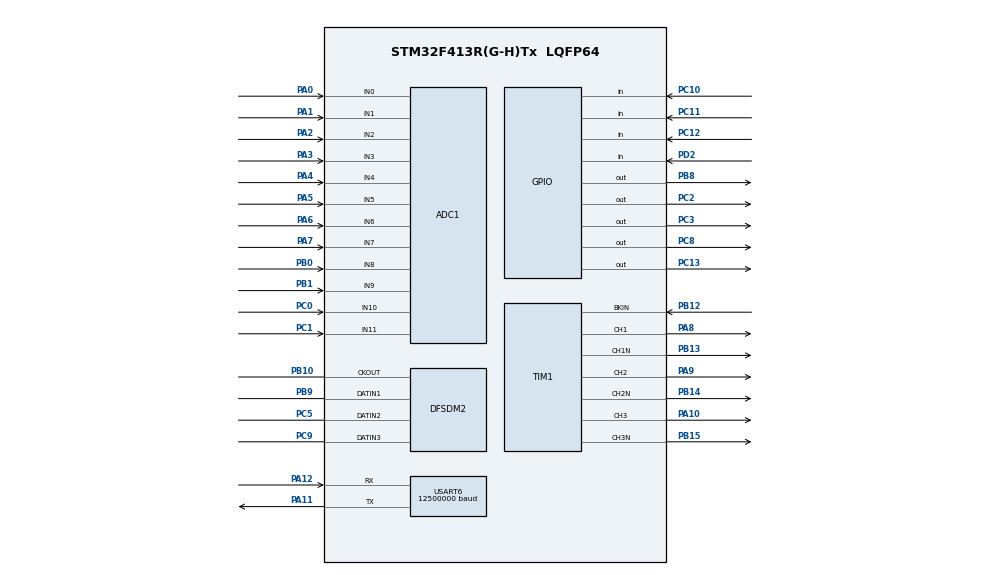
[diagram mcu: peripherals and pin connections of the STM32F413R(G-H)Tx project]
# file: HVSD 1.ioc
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ADC1.Channel-0\#ChannelRegularConversion=ADC_CHANNEL_0
ADC1.NbrOfConversionFlag=1
ADC1.Rank-0\#ChannelRegularConversion=1
ADC1.SamplingTime-0\#ChannelRegularConversion=ADC_SAMPLETIME_3CYCLES
ADC1.master=1
DFSDM2.Divider=11
DFSDM2.FilterOrder_CH0=DFSDM_CHANNEL_FASTSINC_ORDER
DFSDM2.Filter_regChannel_FIL0=DFSDM_CHANNEL_0
DFSDM2.Filter_regChannel_FIL1=DFSDM_CHANNEL_1
DFSDM2.Filter_regChannel_FIL2=DFSDM_CHANNEL_2
DFSDM2.Fosr_FIL0=256
DFSDM2.Fosr_FIL1=256
DFSDM2.Fosr_FIL2=256
DFSDM2.SincOrder_FIL0=DFSDM_FILTER_SINC3_ORDER
DFSDM2.SincOrder_FIL1=DFSDM_FILTER_SINC3_ORDER
DFSDM2.SincOrder_FIL2=DFSDM_FILTER_SINC3_ORDER
Dma.Request0=TIM1_CH1/CH2/CH3
Dma.TIM1_CH1/CH2/CH3.0.Direction=DMA_MEMORY_TO_PERIPH
Dma.TIM1_CH1/CH2/CH3.0.FIFOMode=DMA_FIFOMODE_DISABLE
Dma.TIM1_CH1/CH2/CH3.0.Instance=DMA2_Stream6
Dma.TIM1_CH1/CH2/CH3.0.MemDataAlignment=DMA_MDATAALIGN_HALFWORD
Dma.TIM1_CH1/CH2/CH3.0.MemInc=DMA_MINC_ENABLE
Dma.TIM1_CH1/CH2/CH3.0.Mode=DMA_NORMAL
Dma.TIM1_CH1/CH2/CH3.0.PeriphDataAlignment=DMA_PDATAALIGN_HALFWORD
Dma.TIM1_CH1/CH2/CH3.0.PeriphInc=DMA_PINC_DISABLE
Dma.TIM1_CH1/CH2/CH3.0.Priority=DMA_PRIORITY_HIGH
Mcu.Family=STM32F4
Mcu.Name=STM32F413R(G-H)Tx
Mcu.Package=LQFP64
NVIC.DMA2_Stream6_IRQn=true\:0\:0\:false\:false\:true\:false\:true\:true
NVIC.PriorityGroup=NVIC_PRIORITYGROUP_4
PA0.Signal=ADCx_IN0
PA1.Signal=ADCx_IN1
PA10.Signal=S_TIM1_CH3
PA11.Mode=Asynchronous
PA11.Signal=USART6_TX
PA12.Mode=Asynchronous
PA12.Signal=USART6_RX
PA13.Signal=SYS_JTMS-SWDIO
PA14.Signal=SYS_JTCK-SWCLK
PA2.Signal=ADCx_IN2
PA3.Signal=ADCx_IN3
PA4.Signal=ADCx_IN4
PA5.Signal=ADCx_IN5
PA6.Signal=ADCx_IN6
PA7.Signal=ADCx_IN7
PA8.Signal=S_TIM1_CH1
PA9.Signal=S_TIM1_CH2
PB0.Signal=ADCx_IN8
PB1.Signal=ADCx_IN9
PB10.Signal=S_CKOUTDFSDM2
PB12.Mode=Activate-Break-Input
PB12.Signal=TIM1_BKIN
PB13.Mode=PWM Generation1 CH1 CH1N
PB13.Signal=TIM1_CH1N
PB14.Mode=PWM Generation2 CH2 CH2N
PB14.Signal=TIM1_CH2N
PB15.Mode=PWM Generation3 CH3 CH3N
PB15.Signal=TIM1_CH3N
PB3.Signal=SYS_JTDO-SWO
PB6.Signal=S_TIM4_CH1
PB8.Signal=GPIO_Output
PB9.Signal=S_DATAIN1DFSDM2
PC0.Signal=ADCx_IN10
PC1.Signal=ADCx_IN11
PC10.Signal=GPIO_Input
PC11.Signal=GPIO_Input
PC12.Signal=GPIO_Input
PC13.Signal=GPIO_Output
PC2.Signal=GPIO_Output
PC3.Signal=GPIO_Output
PC5.Signal=S_DATAIN2DFSDM2
PC6.Signal=S_TIM3_CH1
PC7.Signal=S_TIM3_CH2
PC8.Signal=GPIO_Output
PC9.Signal=S_DATAIN3DFSDM2
PD2.Signal=GPIO_Input
ProjectManager.HeapSize=0x200
ProjectManager.StackSize=0x400
ProjectManager.TargetToolchain=STM32CubeIDE
RCC.AHBFreq_Value=100000000
RCC.APB1CLKDivider=RCC_HCLK_DIV2
RCC.APB1Freq_Value=50000000
RCC.APB1TimFreq_Value=100000000
RCC.APB2Freq_Value=100000000
RCC.APB2TimFreq_Value=100000000
RCC.CortexFreq_Value=100000000
RCC.DFSDMSelection=RCC_DFSDM1CLKSOURCE_SYSCLK
RCC.HCLKFreq_Value=100000000
RCC.PLLI2SN=200
RCC.PLLN=200
RCC.SYSCLKFreq_VALUE=100000000
RCC.SYSCLKSource=RCC_SYSCLKSOURCE_PLLCLK
RCC.USBFreq_Value=100000000
RCC.VCOOutputFreq_Value=200000000
SH.ADCx_IN0.0=ADC1_IN0,IN0
SH.ADCx_IN1.0=ADC1_IN1,IN1
SH.ADCx_IN10.0=ADC1_IN10,IN10
SH.ADCx_IN11.0=ADC1_IN11,IN11
SH.ADCx_IN2.0=ADC1_IN2,IN2
SH.ADCx_IN3.0=ADC1_IN3,IN3
SH.ADCx_IN4.0=ADC1_IN4,IN4
SH.ADCx_IN5.0=ADC1_IN5,IN5
SH.ADCx_IN6.0=ADC1_IN6,IN6
SH.ADCx_IN7.0=ADC1_IN7,IN7
SH.ADCx_IN8.0=ADC1_IN8,IN8
SH.ADCx_IN9.0=ADC1_IN9,IN9
SH.S_CKOUTDFSDM2.0=DFSDM2_CKOUT,PDM_SPI_Input_from_ch12_and_Internal_Clock
SH.S_CKOUTDFSDM2.1=DFSDM2_CKOUT,PDM_SPI_Input_from_ch01_and_Internal_Clock
SH.S_CKOUTDFSDM2.2=DFSDM2_CKOUT,PDM_SPI_Input_from_ch23_and_Internal_Clock
SH.S_CKOUTDFSDM2.3=DFSDM2_CKOUT,CKOUT
SH.S_DATAIN1DFSDM2.0=DFSDM2_DATIN1,PDM_SPI_Input_from_ch01_and_Internal_Clock
SH.S_DATAIN2DFSDM2.0=DFSDM2_DATIN2,PDM_SPI_Input_from_ch12_and_Internal_Clock
SH.S_DATAIN3DFSDM2.0=DFSDM2_DATIN3,PDM_SPI_Input_from_ch23_and_Internal_Clock
SH.S_TIM1_CH1.0=TIM1_CH1,PWM Generation1 CH1 CH1N
SH.S_TIM1_CH2.0=TIM1_CH2,PWM Generation2 CH2 CH2N
SH.S_TIM1_CH3.0=TIM1_CH3,PWM Generation3 CH3 CH3N
SH.S_TIM3_CH1.0=TIM3_CH1
SH.S_TIM3_CH2.0=TIM3_CH2
SH.S_TIM4_CH1.0=TIM4_CH1
TIM1.AutoReloadPreload=TIM_AUTORELOAD_PRELOAD_ENABLE
TIM1.Channel-PWM\ Generation1\ CH1\ CH1N=TIM_CHANNEL_1
TIM1.Channel-PWM\ Generation2\ CH2\ CH2N=TIM_CHANNEL_2
TIM1.Channel-PWM\ Generation3\ CH3\ CH3N=TIM_CHANNEL_3
TIM1.Channel-PWM\ Generation4\ No\ Output=TIM_CHANNEL_4
TIM1.CounterMode=TIM_COUNTERMODE_CENTERALIGNED1
TIM1.OCMode_PWM-PWM\ Generation1\ CH1\ CH1N=TIM_OCMODE_PWM1
USART6.BaudRate=12500000
USART6.OverSampling=UART_OVERSAMPLING_8
USART6.VirtualMode=VM_ASYNC
VP_CRC_VS_CRC.Mode=CRC_Activate
VP_TIM1_VS_ClockSourceITR.Mode=TriggerSource_ITR1
VP_TIM1_VS_ControllerModeTrigger.Mode=Trigger Mode
VP_TIM1_VS_no_output4.Mode=PWM Generation4 No Output
board=custom

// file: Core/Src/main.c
/* USER CODE BEGIN Header */
/**
  ******************************************************************************
  * @file           : main.c
  * @brief          : Main program body
  ******************************************************************************
  * @attention
  *
  * <h2><center>&copy; Copyright (c) 2023 STMicroelectronics.
  * All rights reserved.</center></h2>
  *
  * This software component is licensed by ST under BSD 3-Clause license,
  * the "License"; You may not use this file except in compliance with the
  * License. You may obtain a copy of the License at:
  *                        opensource.org/licenses/BSD-3-Clause
  *
  ******************************************************************************
  */
/* USER CODE END Header */
#include "main.h"

/* USER CODE BEGIN Includes */
#include "stdio.h"
/* USER CODE END Includes */

DFSDM_Filter_HandleTypeDef hdfsdm2_filter0;
DFSDM_Filter_HandleTypeDef hdfsdm2_filter1;
DFSDM_Filter_HandleTypeDef hdfsdm2_filter2;
DFSDM_Channel_HandleTypeDef hdfsdm2_channel0;
DFSDM_Channel_HandleTypeDef hdfsdm2_channel1;
DFSDM_Channel_HandleTypeDef hdfsdm2_channel2;

void SystemClock_Config(void);
static void MX_GPIO_Init(void);
static void MX_DMA_Init(void);
static void MX_ADC1_Init(void);
static void MX_TIM1_Init(void);
static void MX_DFSDM2_Init(void);
static void MX_USART6_UART_Init(void);
static void MX_CRC_Init(void);

int main(void)
{

  /* MCU Configuration--------------------------------------------------------*/

  /* Reset of all peripherals, Initializes the Flash interface and the Systick. */
  HAL_Init();

  /* Configure the system clock */
  SystemClock_Config();

  /* Initialize all configured peripherals */
  MX_GPIO_Init();
  MX_DMA_Init();
  MX_ADC1_Init();
  MX_TIM1_Init();
  MX_DFSDM2_Init();
  MX_USART6_UART_Init();
  MX_CRC_Init();
  /* USER CODE BEGIN 2 */
  MX_MotorControl_Init();
  /* USER CODE END 2 */

  /* Infinite loop */
  while (1)
  {
    /* USER CODE BEGIN 3 */
	  printf("hello");
	  HAL_GPIO_TogglePin(GPIOB, GPIO_PIN_8);
	  //HAL_GPIO_TogglePin(GPIOC, GPIO_PIN_13);
	  //HAL_GPIO_TogglePin(GPIOC, GPIO_PIN_2);
	  HAL_GPIO_TogglePin(GPIOC, GPIO_PIN_3);
	  HAL_Delay(1);
  }
  /* USER CODE END 3 */
}

void SystemClock_Config(void)
{
  LL_FLASH_SetLatency(LL_FLASH_LATENCY_3);
  while(LL_FLASH_GetLatency()!= LL_FLASH_LATENCY_3)
  {
  }
  LL_PWR_SetRegulVoltageScaling(LL_PWR_REGU_VOLTAGE_SCALE1);
  LL_RCC_HSI_SetCalibTrimming(16);
  LL_RCC_HSI_Enable();

   /* Wait till HSI is ready */
  while(LL_RCC_HSI_IsReady() != 1)
  {

  }
  LL_RCC_PLL_ConfigDomain_SYS(LL_RCC_PLLSOURCE_HSI, LL_RCC_PLLM_DIV_16, 200, LL_RCC_PLLP_DIV_2);
  LL_RCC_PLL_Enable();

   /* Wait till PLL is ready */
  while(LL_RCC_PLL_IsReady() != 1)
  {

  }
  while (LL_PWR_IsActiveFlag_VOS() == 0)
  {
  }
  LL_RCC_SetAHBPrescaler(LL_RCC_SYSCLK_DIV_1);
  LL_RCC_SetAPB1Prescaler(LL_RCC_APB1_DIV_2);
  LL_RCC_SetAPB2Prescaler(LL_RCC_APB2_DIV_1);
  LL_RCC_SetSysClkSource(LL_RCC_SYS_CLKSOURCE_PLL);

   /* Wait till System clock is ready */
  while(LL_RCC_GetSysClkSource() != LL_RCC_SYS_CLKSOURCE_STATUS_PLL)
  {

  }
  LL_SetSystemCoreClock(100000000);

   /* Update the time base */
  if (HAL_InitTick (TICK_INT_PRIORITY) != HAL_OK)
  {
    Error_Handler();
  }
  LL_RCC_SetTIMPrescaler(LL_RCC_TIM_PRESCALER_TWICE);
}

static void MX_ADC1_Init(void)
{

  LL_ADC_InitTypeDef ADC_InitStruct = {0};
  LL_ADC_REG_InitTypeDef ADC_REG_InitStruct = {0};
  LL_ADC_CommonInitTypeDef ADC_CommonInitStruct = {0};

  LL_GPIO_InitTypeDef GPIO_InitStruct = {0};

  /* Peripheral clock enable */
  LL_APB2_GRP1_EnableClock(LL_APB2_GRP1_PERIPH_ADC1);

  LL_AHB1_GRP1_EnableClock(LL_AHB1_GRP1_PERIPH_GPIOC);
  LL_AHB1_GRP1_EnableClock(LL_AHB1_GRP1_PERIPH_GPIOA);
  LL_AHB1_GRP1_EnableClock(LL_AHB1_GRP1_PERIPH_GPIOB);
  /**ADC1 GPIO Configuration
  PC0   ------> ADC1_IN10
  PC1   ------> ADC1_IN11
  PA0   ------> ADC1_IN0
  PA1   ------> ADC1_IN1
  PA2   ------> ADC1_IN2
  PA3   ------> ADC1_IN3
  PA4   ------> ADC1_IN4
  PA5   ------> ADC1_IN5
  PA6   ------> ADC1_IN6
  PA7   ------> ADC1_IN7
  PB0   ------> ADC1_IN8
  PB1   ------> ADC1_IN9
  */
  GPIO_InitStruct.Pin = LL_GPIO_PIN_0|LL_GPIO_PIN_1;
  GPIO_InitStruct.Mode = LL_GPIO_MODE_ANALOG;
  GPIO_InitStruct.Pull = LL_GPIO_PULL_NO;
  LL_GPIO_Init(GPIOC, &GPIO_InitStruct);

  GPIO_InitStruct.Pin = LL_GPIO_PIN_0|LL_GPIO_PIN_1|LL_GPIO_PIN_2|LL_GPIO_PIN_3
                          |LL_GPIO_PIN_4|LL_GPIO_PIN_5|LL_GPIO_PIN_6|LL_GPIO_PIN_7;
  GPIO_InitStruct.Mode = LL_GPIO_MODE_ANALOG;
  GPIO_InitStruct.Pull = LL_GPIO_PULL_NO;
  LL_GPIO_Init(GPIOA, &GPIO_InitStruct);

  GPIO_InitStruct.Pin = LL_GPIO_PIN_0|LL_GPIO_PIN_1;
  GPIO_InitStruct.Mode = LL_GPIO_MODE_ANALOG;
  GPIO_InitStruct.Pull = LL_GPIO_PULL_NO;
  LL_GPIO_Init(GPIOB, &GPIO_InitStruct);

  /** Common config
  */
  ADC_InitStruct.Resolution = LL_ADC_RESOLUTION_12B;
  ADC_InitStruct.DataAlignment = LL_ADC_DATA_ALIGN_RIGHT;
  ADC_InitStruct.SequencersScanMode = LL_ADC_SEQ_SCAN_DISABLE;
  LL_ADC_Init(ADC1, &ADC_InitStruct);
  ADC_REG_InitStruct.TriggerSource = LL_ADC_REG_TRIG_SOFTWARE;
  ADC_REG_InitStruct.SequencerLength = LL_ADC_REG_SEQ_SCAN_DISABLE;
  ADC_REG_InitStruct.SequencerDiscont = LL_ADC_REG_SEQ_DISCONT_DISABLE;
  ADC_REG_InitStruct.ContinuousMode = LL_ADC_REG_CONV_SINGLE;
  ADC_REG_InitStruct.DMATransfer = LL_ADC_REG_DMA_TRANSFER_NONE;
  LL_ADC_REG_Init(ADC1, &ADC_REG_InitStruct);
  LL_ADC_REG_SetFlagEndOfConversion(ADC1, LL_ADC_REG_FLAG_EOC_UNITARY_CONV);
  ADC_CommonInitStruct.CommonClock = LL_ADC_CLOCK_SYNC_PCLK_DIV4;
  LL_ADC_CommonInit(__LL_ADC_COMMON_INSTANCE(ADC1), &ADC_CommonInitStruct);

  /** Configure Regular Channel
  */
  LL_ADC_REG_SetSequencerRanks(ADC1, LL_ADC_REG_RANK_1, LL_ADC_CHANNEL_0);
  LL_ADC_SetChannelSamplingTime(ADC1, LL_ADC_CHANNEL_0, LL_ADC_SAMPLINGTIME_3CYCLES);

}

static void MX_CRC_Init(void)
{

  /* Peripheral clock enable */
  LL_AHB1_GRP1_EnableClock(LL_AHB1_GRP1_PERIPH_CRC);

}

static void MX_DFSDM2_Init(void)
{

  hdfsdm2_filter0.Instance = DFSDM2_Filter0;
  hdfsdm2_filter0.Init.RegularParam.Trigger = DFSDM_FILTER_SW_TRIGGER;
  hdfsdm2_filter0.Init.RegularParam.FastMode = DISABLE;
  hdfsdm2_filter0.Init.RegularParam.DmaMode = DISABLE;
  hdfsdm2_filter0.Init.FilterParam.SincOrder = DFSDM_FILTER_SINC3_ORDER;
  hdfsdm2_filter0.Init.FilterParam.Oversampling = 256;
  hdfsdm2_filter0.Init.FilterParam.IntOversampling = 1;
  if (HAL_DFSDM_FilterInit(&hdfsdm2_filter0) != HAL_OK)
  {
    Error_Handler();
  }
  hdfsdm2_filter1.Instance = DFSDM2_Filter1;
  hdfsdm2_filter1.Init.RegularParam.Trigger = DFSDM_FILTER_SW_TRIGGER;
  hdfsdm2_filter1.Init.RegularParam.FastMode = DISABLE;
  hdfsdm2_filter1.Init.RegularParam.DmaMode = DISABLE;
  hdfsdm2_filter1.Init.FilterParam.SincOrder = DFSDM_FILTER_SINC3_ORDER;
  hdfsdm2_filter1.Init.FilterParam.Oversampling = 256;
  hdfsdm2_filter1.Init.FilterParam.IntOversampling = 1;
  if (HAL_DFSDM_FilterInit(&hdfsdm2_filter1) != HAL_OK)
  {
    Error_Handler();
  }
  hdfsdm2_filter2.Instance = DFSDM2_Filter2;
  hdfsdm2_filter2.Init.RegularParam.Trigger = DFSDM_FILTER_SW_TRIGGER;
  hdfsdm2_filter2.Init.RegularParam.FastMode = DISABLE;
  hdfsdm2_filter2.Init.RegularParam.DmaMode = DISABLE;
  hdfsdm2_filter2.Init.FilterParam.SincOrder = DFSDM_FILTER_SINC3_ORDER;
  hdfsdm2_filter2.Init.FilterParam.Oversampling = 256;
  hdfsdm2_filter2.Init.FilterParam.IntOversampling = 1;
  if (HAL_DFSDM_FilterInit(&hdfsdm2_filter2) != HAL_OK)
  {
    Error_Handler();
  }
  hdfsdm2_channel0.Instance = DFSDM2_Channel0;
  hdfsdm2_channel0.Init.OutputClock.Activation = ENABLE;
  hdfsdm2_channel0.Init.OutputClock.Selection = DFSDM_CHANNEL_OUTPUT_CLOCK_SYSTEM;
  hdfsdm2_channel0.Init.OutputClock.Divider = 11;
  hdfsdm2_channel0.Init.Input.Multiplexer = DFSDM_CHANNEL_EXTERNAL_INPUTS;
  hdfsdm2_channel0.Init.Input.DataPacking = DFSDM_CHANNEL_STANDARD_MODE;
  hdfsdm2_channel0.Init.Input.Pins = DFSDM_CHANNEL_FOLLOWING_CHANNEL_PINS;
  hdfsdm2_channel0.Init.SerialInterface.Type = DFSDM_CHANNEL_SPI_RISING;
  hdfsdm2_channel0.Init.SerialInterface.SpiClock = DFSDM_CHANNEL_SPI_CLOCK_INTERNAL;
  hdfsdm2_channel0.Init.Awd.FilterOrder = DFSDM_CHANNEL_FASTSINC_ORDER;
  hdfsdm2_channel0.Init.Awd.Oversampling = 1;
  hdfsdm2_channel0.Init.Offset = 0;
  hdfsdm2_channel0.Init.RightBitShift = 0x00;
  if (HAL_DFSDM_ChannelInit(&hdfsdm2_channel0) != HAL_OK)
  {
    Error_Handler();
  }
  hdfsdm2_channel1.Instance = DFSDM2_Channel1;
  hdfsdm2_channel1.Init.OutputClock.Activation = ENABLE;
  hdfsdm2_channel1.Init.OutputClock.Selection = DFSDM_CHANNEL_OUTPUT_CLOCK_SYSTEM;
  hdfsdm2_channel1.Init.OutputClock.Divider = 11;
  hdfsdm2_channel1.Init.Input.Multiplexer = DFSDM_CHANNEL_EXTERNAL_INPUTS;
  hdfsdm2_channel1.Init.Input.DataPacking = DFSDM_CHANNEL_STANDARD_MODE;
  hdfsdm2_channel1.Init.Input.Pins = DFSDM_CHANNEL_FOLLOWING_CHANNEL_PINS;
  hdfsdm2_channel1.Init.SerialInterface.Type = DFSDM_CHANNEL_SPI_RISING;
  hdfsdm2_channel1.Init.SerialInterface.SpiClock = DFSDM_CHANNEL_SPI_CLOCK_INTERNAL;
  hdfsdm2_channel1.Init.Awd.FilterOrder = DFSDM_CHANNEL_FASTSINC_ORDER;
  hdfsdm2_channel1.Init.Awd.Oversampling = 1;
  hdfsdm2_channel1.Init.Offset = 0;
  hdfsdm2_channel1.Init.RightBitShift = 0x00;
  if (HAL_DFSDM_ChannelInit(&hdfsdm2_channel1) != HAL_OK)
  {
    Error_Handler();
  }
  hdfsdm2_channel2.Instance = DFSDM2_Channel2;
  hdfsdm2_channel2.Init.OutputClock.Activation = ENABLE;
  hdfsdm2_channel2.Init.OutputClock.Selection = DFSDM_CHANNEL_OUTPUT_CLOCK_SYSTEM;
  hdfsdm2_channel2.Init.OutputClock.Divider = 11;
  hdfsdm2_channel2.Init.Input.Multiplexer = DFSDM_CHANNEL_EXTERNAL_INPUTS;
  hdfsdm2_channel2.Init.Input.DataPacking = DFSDM_CHANNEL_STANDARD_MODE;
  hdfsdm2_channel2.Init.Input.Pins = DFSDM_CHANNEL_FOLLOWING_CHANNEL_PINS;
  hdfsdm2_channel2.Init.SerialInterface.Type = DFSDM_CHANNEL_SPI_RISING;
  hdfsdm2_channel2.Init.SerialInterface.SpiClock = DFSDM_CHANNEL_SPI_CLOCK_INTERNAL;
  hdfsdm2_channel2.Init.Awd.FilterOrder = DFSDM_CHANNEL_FASTSINC_ORDER;
  hdfsdm2_channel2.Init.Awd.Oversampling = 1;
  hdfsdm2_channel2.Init.Offset = 0;
  hdfsdm2_channel2.Init.RightBitShift = 0x00;
  if (HAL_DFSDM_ChannelInit(&hdfsdm2_channel2) != HAL_OK)
  {
    Error_Handler();
  }
  if (HAL_DFSDM_FilterConfigRegChannel(&hdfsdm2_filter0, DFSDM_CHANNEL_0, DFSDM_CONTINUOUS_CONV_ON) != HAL_OK)
  {
    Error_Handler();
  }
  if (HAL_DFSDM_FilterConfigRegChannel(&hdfsdm2_filter1, DFSDM_CHANNEL_1, DFSDM_CONTINUOUS_CONV_ON) != HAL_OK)
  {
    Error_Handler();
  }
  if (HAL_DFSDM_FilterConfigRegChannel(&hdfsdm2_filter2, DFSDM_CHANNEL_2, DFSDM_CONTINUOUS_CONV_ON) != HAL_OK)
  {
    Error_Handler();
  }

}

static void MX_TIM1_Init(void)
{

  LL_TIM_InitTypeDef TIM_InitStruct = {0};
  LL_TIM_OC_InitTypeDef TIM_OC_InitStruct = {0};
  LL_TIM_BDTR_InitTypeDef TIM_BDTRInitStruct = {0};

  LL_GPIO_InitTypeDef GPIO_InitStruct = {0};

  /* Peripheral clock enable */
  LL_APB2_GRP1_EnableClock(LL_APB2_GRP1_PERIPH_TIM1);

  LL_AHB1_GRP1_EnableClock(LL_AHB1_GRP1_PERIPH_GPIOB);
  /**TIM1 GPIO Configuration
  PB12   ------> TIM1_BKIN
  */
  GPIO_InitStruct.Pin = LL_GPIO_PIN_12;
  GPIO_InitStruct.Mode = LL_GPIO_MODE_ALTERNATE;
  GPIO_InitStruct.Speed = LL_GPIO_SPEED_FREQ_LOW;
  GPIO_InitStruct.OutputType = LL_GPIO_OUTPUT_PUSHPULL;
  GPIO_InitStruct.Pull = LL_GPIO_PULL_NO;
  GPIO_InitStruct.Alternate = LL_GPIO_AF_1;
  LL_GPIO_Init(GPIOB, &GPIO_InitStruct);

  /* TIM1 DMA Init */

  /* TIM1_CH1_CH2_CH3 Init */
  LL_DMA_SetChannelSelection(DMA2, LL_DMA_STREAM_6, LL_DMA_CHANNEL_0);

  LL_DMA_SetDataTransferDirection(DMA2, LL_DMA_STREAM_6, LL_DMA_DIRECTION_MEMORY_TO_PERIPH);

  LL_DMA_SetStreamPriorityLevel(DMA2, LL_DMA_STREAM_6, LL_DMA_PRIORITY_HIGH);

  LL_DMA_SetMode(DMA2, LL_DMA_STREAM_6, LL_DMA_MODE_NORMAL);

  LL_DMA_SetPeriphIncMode(DMA2, LL_DMA_STREAM_6, LL_DMA_PERIPH_NOINCREMENT);

  LL_DMA_SetMemoryIncMode(DMA2, LL_DMA_STREAM_6, LL_DMA_MEMORY_INCREMENT);

  LL_DMA_SetPeriphSize(DMA2, LL_DMA_STREAM_6, LL_DMA_PDATAALIGN_HALFWORD);

  LL_DMA_SetMemorySize(DMA2, LL_DMA_STREAM_6, LL_DMA_MDATAALIGN_HALFWORD);

  LL_DMA_DisableFifoMode(DMA2, LL_DMA_STREAM_6);

  TIM_InitStruct.Prescaler = 0;
  TIM_InitStruct.CounterMode = LL_TIM_COUNTERMODE_CENTER_DOWN;
  TIM_InitStruct.Autoreload = 65535;
  TIM_InitStruct.ClockDivision = LL_TIM_CLOCKDIVISION_DIV1;
  TIM_InitStruct.RepetitionCounter = 0;
  LL_TIM_Init(TIM1, &TIM_InitStruct);
  LL_TIM_EnableARRPreload(TIM1);
  LL_TIM_OC_EnablePreload(TIM1, LL_TIM_CHANNEL_CH1);
  TIM_OC_InitStruct.OCMode = LL_TIM_OCMODE_PWM1;
  TIM_OC_InitStruct.OCState = LL_TIM_OCSTATE_DISABLE;
  TIM_OC_InitStruct.OCNState = LL_TIM_OCSTATE_DISABLE;
  TIM_OC_InitStruct.CompareValue = 0;
  TIM_OC_InitStruct.OCPolarity = LL_TIM_OCPOLARITY_HIGH;
  TIM_OC_InitStruct.OCNPolarity = LL_TIM_OCPOLARITY_HIGH;
  TIM_OC_InitStruct.OCIdleState = LL_TIM_OCIDLESTATE_LOW;
  TIM_OC_InitStruct.OCNIdleState = LL_TIM_OCIDLESTATE_LOW;
  LL_TIM_OC_Init(TIM1, LL_TIM_CHANNEL_CH1, &TIM_OC_InitStruct);
  LL_TIM_OC_DisableFast(TIM1, LL_TIM_CHANNEL_CH1);
  LL_TIM_OC_EnablePreload(TIM1, LL_TIM_CHANNEL_CH2);
  LL_TIM_OC_Init(TIM1, LL_TIM_CHANNEL_CH2, &TIM_OC_InitStruct);
  LL_TIM_OC_DisableFast(TIM1, LL_TIM_CHANNEL_CH2);
  LL_TIM_OC_EnablePreload(TIM1, LL_TIM_CHANNEL_CH3);
  LL_TIM_OC_Init(TIM1, LL_TIM_CHANNEL_CH3, &TIM_OC_InitStruct);
  LL_TIM_OC_DisableFast(TIM1, LL_TIM_CHANNEL_CH3);
  LL_TIM_OC_EnablePreload(TIM1, LL_TIM_CHANNEL_CH4);
  LL_TIM_OC_Init(TIM1, LL_TIM_CHANNEL_CH4, &TIM_OC_InitStruct);
  LL_TIM_OC_DisableFast(TIM1, LL_TIM_CHANNEL_CH4);
  LL_TIM_SetTriggerInput(TIM1, LL_TIM_TS_ITR1);
  LL_TIM_SetSlaveMode(TIM1, LL_TIM_SLAVEMODE_TRIGGER);
  LL_TIM_DisableIT_TRIG(TIM1);
  LL_TIM_DisableDMAReq_TRIG(TIM1);
  LL_TIM_SetTriggerOutput(TIM1, LL_TIM_TRGO_RESET);
  LL_TIM_DisableMasterSlaveMode(TIM1);
  TIM_BDTRInitStruct.OSSRState = LL_TIM_OSSR_DISABLE;
  TIM_BDTRInitStruct.OSSIState = LL_TIM_OSSI_DISABLE;
  TIM_BDTRInitStruct.LockLevel = LL_TIM_LOCKLEVEL_OFF;
  TIM_BDTRInitStruct.DeadTime = 0;
  TIM_BDTRInitStruct.BreakState = LL_TIM_BREAK_ENABLE;
  TIM_BDTRInitStruct.BreakPolarity = LL_TIM_BREAK_POLARITY_HIGH;
  TIM_BDTRInitStruct.AutomaticOutput = LL_TIM_AUTOMATICOUTPUT_DISABLE;
  LL_TIM_BDTR_Init(TIM1, &TIM_BDTRInitStruct);
  LL_AHB1_GRP1_EnableClock(LL_AHB1_GRP1_PERIPH_GPIOB);
  LL_AHB1_GRP1_EnableClock(LL_AHB1_GRP1_PERIPH_GPIOA);
  /**TIM1 GPIO Configuration
  PB13   ------> TIM1_CH1N
  PB14   ------> TIM1_CH2N
  PB15   ------> TIM1_CH3N
  PA8   ------> TIM1_CH1
  PA9   ------> TIM1_CH2
  PA10   ------> TIM1_CH3
  */
  GPIO_InitStruct.Pin = LL_GPIO_PIN_13|LL_GPIO_PIN_14|LL_GPIO_PIN_15;
  GPIO_InitStruct.Mode = LL_GPIO_MODE_ALTERNATE;
  GPIO_InitStruct.Speed = LL_GPIO_SPEED_FREQ_LOW;
  GPIO_InitStruct.OutputType = LL_GPIO_OUTPUT_PUSHPULL;
  GPIO_InitStruct.Pull = LL_GPIO_PULL_NO;
  GPIO_InitStruct.Alternate = LL_GPIO_AF_1;
  LL_GPIO_Init(GPIOB, &GPIO_InitStruct);

  GPIO_InitStruct.Pin = LL_GPIO_PIN_8|LL_GPIO_PIN_9|LL_GPIO_PIN_10;
  GPIO_InitStruct.Mode = LL_GPIO_MODE_ALTERNATE;
  GPIO_InitStruct.Speed = LL_GPIO_SPEED_FREQ_LOW;
  GPIO_InitStruct.OutputType = LL_GPIO_OUTPUT_PUSHPULL;
  GPIO_InitStruct.Pull = LL_GPIO_PULL_NO;
  GPIO_InitStruct.Alternate = LL_GPIO_AF_1;
  LL_GPIO_Init(GPIOA, &GPIO_InitStruct);

}

static void MX_USART6_UART_Init(void)
{

  LL_USART_InitTypeDef USART_InitStruct = {0};

  LL_GPIO_InitTypeDef GPIO_InitStruct = {0};

  /* Peripheral clock enable */
  LL_APB2_GRP1_EnableClock(LL_APB2_GRP1_PERIPH_USART6);

  LL_AHB1_GRP1_EnableClock(LL_AHB1_GRP1_PERIPH_GPIOA);
  /**USART6 GPIO Configuration
  PA11   ------> USART6_TX
  PA12   ------> USART6_RX
  */
  GPIO_InitStruct.Pin = LL_GPIO_PIN_11|LL_GPIO_PIN_12;
  GPIO_InitStruct.Mode = LL_GPIO_MODE_ALTERNATE;
  GPIO_InitStruct.Speed = LL_GPIO_SPEED_FREQ_VERY_HIGH;
  GPIO_InitStruct.OutputType = LL_GPIO_OUTPUT_PUSHPULL;
  GPIO_InitStruct.Pull = LL_GPIO_PULL_NO;
  GPIO_InitStruct.Alternate = LL_GPIO_AF_8;
  LL_GPIO_Init(GPIOA, &GPIO_InitStruct);

  USART_InitStruct.BaudRate = 12500000;
  USART_InitStruct.DataWidth = LL_USART_DATAWIDTH_8B;
  USART_InitStruct.StopBits = LL_USART_STOPBITS_1;
  USART_InitStruct.Parity = LL_USART_PARITY_NONE;
  USART_InitStruct.TransferDirection = LL_USART_DIRECTION_TX_RX;
  USART_InitStruct.HardwareFlowControl = LL_USART_HWCONTROL_NONE;
  USART_InitStruct.OverSampling = LL_USART_OVERSAMPLING_8;
  LL_USART_Init(USART6, &USART_InitStruct);
  LL_USART_ConfigAsyncMode(USART6);
  LL_USART_Enable(USART6);

}

static void MX_DMA_Init(void)
{

  /* Init with LL driver */
  /* DMA controller clock enable */
  LL_AHB1_GRP1_EnableClock(LL_AHB1_GRP1_PERIPH_DMA2);

  /* DMA interrupt init */
  /* DMA2_Stream6_IRQn interrupt configuration */
  NVIC_SetPriority(DMA2_Stream6_IRQn, NVIC_EncodePriority(NVIC_GetPriorityGrouping(),0, 0));
  NVIC_EnableIRQ(DMA2_Stream6_IRQn);

}

static void MX_GPIO_Init(void)
{
  LL_GPIO_InitTypeDef GPIO_InitStruct = {0};

  /* GPIO Ports Clock Enable */
  LL_AHB1_GRP1_EnableClock(LL_AHB1_GRP1_PERIPH_GPIOC);
  LL_AHB1_GRP1_EnableClock(LL_AHB1_GRP1_PERIPH_GPIOA);
  LL_AHB1_GRP1_EnableClock(LL_AHB1_GRP1_PERIPH_GPIOB);
  LL_AHB1_GRP1_EnableClock(LL_AHB1_GRP1_PERIPH_GPIOD);

  /**/
  LL_GPIO_ResetOutputPin(GPIOC, LL_GPIO_PIN_13|LL_GPIO_PIN_2|LL_GPIO_PIN_3|LL_GPIO_PIN_8);

  /**/
  LL_GPIO_ResetOutputPin(GPIOB, LL_GPIO_PIN_8);

  /**/
  GPIO_InitStruct.Pin = LL_GPIO_PIN_13|LL_GPIO_PIN_2|LL_GPIO_PIN_3|LL_GPIO_PIN_8;
  GPIO_InitStruct.Mode = LL_GPIO_MODE_OUTPUT;
  GPIO_InitStruct.Speed = LL_GPIO_SPEED_FREQ_LOW;
  GPIO_InitStruct.OutputType = LL_GPIO_OUTPUT_PUSHPULL;
  GPIO_InitStruct.Pull = LL_GPIO_PULL_NO;
  LL_GPIO_Init(GPIOC, &GPIO_InitStruct);

  /**/
  GPIO_InitStruct.Pin = LL_GPIO_PIN_6|LL_GPIO_PIN_7;
  GPIO_InitStruct.Mode = LL_GPIO_MODE_ALTERNATE;
  GPIO_InitStruct.Speed = LL_GPIO_SPEED_FREQ_LOW;
  GPIO_InitStruct.OutputType = LL_GPIO_OUTPUT_PUSHPULL;
  GPIO_InitStruct.Pull = LL_GPIO_PULL_NO;
  GPIO_InitStruct.Alternate = LL_GPIO_AF_2;
  LL_GPIO_Init(GPIOC, &GPIO_InitStruct);

  /**/
  GPIO_InitStruct.Pin = LL_GPIO_PIN_10|LL_GPIO_PIN_11|LL_GPIO_PIN_12;
  GPIO_InitStruct.Mode = LL_GPIO_MODE_INPUT;
  GPIO_InitStruct.Pull = LL_GPIO_PULL_NO;
  LL_GPIO_Init(GPIOC, &GPIO_InitStruct);

  /**/
  GPIO_InitStruct.Pin = LL_GPIO_PIN_2;
  GPIO_InitStruct.Mode = LL_GPIO_MODE_INPUT;
  GPIO_InitStruct.Pull = LL_GPIO_PULL_NO;
  LL_GPIO_Init(GPIOD, &GPIO_InitStruct);

  /**/
  GPIO_InitStruct.Pin = LL_GPIO_PIN_6;
  GPIO_InitStruct.Mode = LL_GPIO_MODE_ALTERNATE;
  GPIO_InitStruct.Speed = LL_GPIO_SPEED_FREQ_LOW;
  GPIO_InitStruct.OutputType = LL_GPIO_OUTPUT_PUSHPULL;
  GPIO_InitStruct.Pull = LL_GPIO_PULL_NO;
  GPIO_InitStruct.Alternate = LL_GPIO_AF_2;
  LL_GPIO_Init(GPIOB, &GPIO_InitStruct);

  /**/
  GPIO_InitStruct.Pin = LL_GPIO_PIN_8;
  GPIO_InitStruct.Mode = LL_GPIO_MODE_OUTPUT;
  GPIO_InitStruct.Speed = LL_GPIO_SPEED_FREQ_LOW;
  GPIO_InitStruct.OutputType = LL_GPIO_OUTPUT_PUSHPULL;
  GPIO_InitStruct.Pull = LL_GPIO_PULL_NO;
  LL_GPIO_Init(GPIOB, &GPIO_InitStruct);

}

void Error_Handler(void)
{
  __disable_irq();
  while (1)
  {
  }
}
